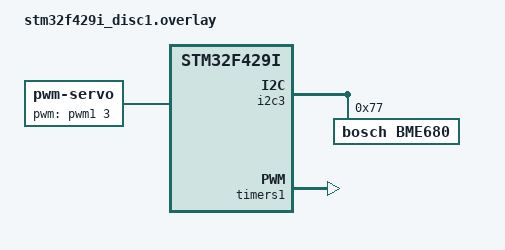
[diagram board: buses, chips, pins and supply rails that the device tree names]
/ {
    servo: servo {
        compatible = "pwm-servo";
        pwms = <&pwm1 3 PWM_MSEC(20) PWM_POLARITY_NORMAL>;
        min-pulse = <PWM_USEC(700)>;
        max-pulse = <PWM_USEC(2500)>;
    };

    chosen {
    perso,bme680 = &bme680;
    };
};

&i2c3 {
    bme680: bme680@77 {
        compatible = "bosch,bme680";
        reg = <0x77>;
        label = "BME680";
    };
};

&timers1 {
    status = "okay";
    st,prescaler = <1000>;

    pwm1: pwm {
        status = "okay";
        pinctrl-0 = <&tim1_ch3_pe13>;
        pinctrl-names = "default";
    };
};
